AUTOSAR XML (schema 00046)
package /ComponentTypes
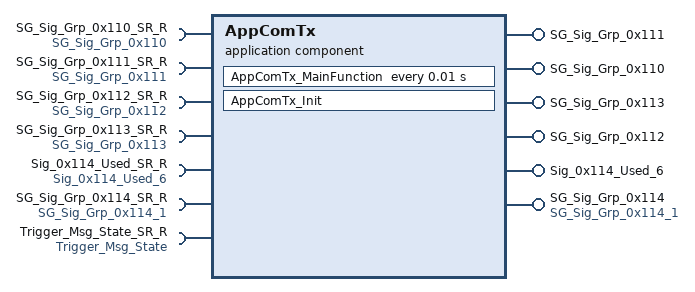
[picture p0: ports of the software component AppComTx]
  application sw component type AppComTx
    4 x provide port:
      SG_Sig_Grp_0x111: nonqueued-sender-com-spec{data-element=SG_Sig_Grp_0x111, init-value=fields=[Button1_State:0, Button2_State:0, Button3_State:0, Button4_State:0]}, provided-interface=SG_Sig_Grp_0x111
      SG_Sig_Grp_0x110: nonqueued-sender-com-spec{data-element=SG_Sig_Grp_0x110, init-value=fields=[Led1_State:0, Led2_State:0, Led3_State:0, Led4_State:0]}, provided-interface=SG_Sig_Grp_0x110
      SG_Sig_Grp_0x113: nonqueued-sender-com-spec{data-element=SG_Sig_Grp_0x113, init-value=fields=System_Run_Time:20}, provided-interface=SG_Sig_Grp_0x113
      SG_Sig_Grp_0x112: nonqueued-sender-com-spec{data-element=SG_Sig_Grp_0x112, uses-end-to-end-protection=true, init-value=fields=[PowerMode:0, SupA_Checksum_0x112:0, SupA_Counter_0x112:0]}, provided-interface=SG_Sig_Grp_0x112
    4 x require port:
      SG_Sig_Grp_0x110_SR_R: nonqueued-receiver-com-spec{data-element=SG_Sig_Grp_0x110, filter=data-filter-type=ALWAYS, init-value=fields=[Led1_State:0, Led2_State:0, Led3_State:0, Led4_State:0]}, required-interface=SG_Sig_Grp_0x110
      SG_Sig_Grp_0x111_SR_R: nonqueued-receiver-com-spec{data-element=SG_Sig_Grp_0x111, filter=data-filter-type=ALWAYS, init-value=fields=[Button1_State:0, Button2_State:0, Button3_State:0, Button4_State:0]}, required-interface=SG_Sig_Grp_0x111
      SG_Sig_Grp_0x112_SR_R: nonqueued-receiver-com-spec{data-element=SG_Sig_Grp_0x112, filter=data-filter-type=ALWAYS, init-value=fields=[PowerMode:0, SupA_Checksum_0x112:0, SupA_Counter_0x112:0]}, required-interface=SG_Sig_Grp_0x112
      SG_Sig_Grp_0x113_SR_R: nonqueued-receiver-com-spec{data-element=SG_Sig_Grp_0x113, filter=data-filter-type=ALWAYS, init-value=fields=System_Run_Time:20}, required-interface=SG_Sig_Grp_0x113
    provide port Sig_0x114_Used_6: nonqueued-sender-com-spec{data-element=Sig_0x114_Used_6, init-value=0}, provided-interface=Sig_0x114_Used_6
    require port Sig_0x114_Used_SR_R: nonqueued-receiver-com-spec{data-element=Sig_0x114_Used_6, filter=data-filter-type=ALWAYS, init-value=0}, required-interface=Sig_0x114_Used_6
    provide port SG_Sig_Grp_0x114: nonqueued-sender-com-spec{data-element=SG_Sig_Grp_0x114, init-value=fields=[Sig_0x114_Used_1:0, Sig_0x114_Used_2:0, Sig_0x114_Used_3:0, Sig_0x114_Used_4:0, Sig_0x114_Used_5:0]}, provided-interface=SG_Sig_Grp_0x114_1
    require port SG_Sig_Grp_0x114_SR_R: nonqueued-receiver-com-spec{data-element=SG_Sig_Grp_0x114, filter=data-filter-type=ALWAYS, init-value=fields=[Sig_0x114_Used_1:0, Sig_0x114_Used_2:0, Sig_0x114_Used_3:0, Sig_0x114_Used_4:0, Sig_0x114_Used_5:0]}, required-interface=SG_Sig_Grp_0x114_1
    require port Trigger_Msg_State_SR_R: nonqueued-receiver-com-spec{data-element=Trigger_Msg_State, filter=data-filter-type=ALWAYS}, required-interface=Trigger_Msg_State
    behavior AppComTx_InternalBehavior
      init event AppComTx_InitEvent: start-on-event=AppComTx_Init
      timing event TMT_AppComTx_MainFunction: start-on-event=AppComTx_MainFunction, period=0.01
      runnable AppComTx_Init
      runnable AppComTx_MainFunction
        data-receive-point-by-arguments:
          7 x access:
            REC_SG_Sig_Grp_0x{110..113}_SR_R_SG_Sig_Grp_0x{110..113}: accessed-variable=SG_Sig_Grp_0x{110..113}_SR_R.SG_Sig_Grp_0x{110..113}
            REC_Sig_0x114_Used_SR_R_Sig_0x114_Used_6: accessed-variable=Sig_0x114_Used_SR_R.Sig_0x114_Used_6
            REC_SG_Sig_Grp_0x114_SR_R_SG_Sig_Grp_0x114: accessed-variable=SG_Sig_Grp_0x114_SR_R.SG_Sig_Grp_0x114
            REC_Trigger_Msg_State_SR_R_Trigger_Msg_State: accessed-variable=Trigger_Msg_State_SR_R.Trigger_Msg_State
        data-send-points:
          6 x access:
            SEND_SG_Sig_Grp_0x{110..113}_SG_Sig_Grp_0x{110..113}: accessed-variable=SG_Sig_Grp_0x{110..113}.SG_Sig_Grp_0x{110..113}
            SEND_Sig_0x114_Used_6_Sig_0x114_Used_6: accessed-variable=Sig_0x114_Used_6.Sig_0x114_Used_6
            SEND_SG_Sig_Grp_0x114_SG_Sig_Grp_0x114: accessed-variable=SG_Sig_Grp_0x114.SG_Sig_Grp_0x114
  swc implementation AppComTx_Implementation: behavior=AppComTx_InternalBehavior
